LIN_description_file;
LIN_protocol_version = "1.3";
LIN_language_version = "1.3";
LIN_speed = 9.6 kbps;

Nodes {
  Master: BSGEvo, 5 ms, 0.1 ms ;
  Slaves: DNR ;
}

Diagnostic_addresses {
  DNR : 255;
}

Signals {
  DNR_Position_RM: 1, 0, DNR, BSGEvo ;
  DNR_Position_R1: 1, 0, DNR, BSGEvo ;
  DNR_Position_N: 1, 0, DNR, BSGEvo ;
  DNR_Position_D1: 1, 0, DNR, BSGEvo ;
  DNR_Position_D4: 1, 0, DNR, BSGEvo ;
  DNR_Position_D7: 1, 0, DNR, BSGEvo ;
  DNR_Position_DM: 1, 0, DNR, BSGEvo ;
  DNR_Position_MsgCounter: 4, 0, DNR, BSGEvo ;
  DNR_Position_SwitchStatus: 4, 0, DNR, BSGEvo ;
}

Frames {
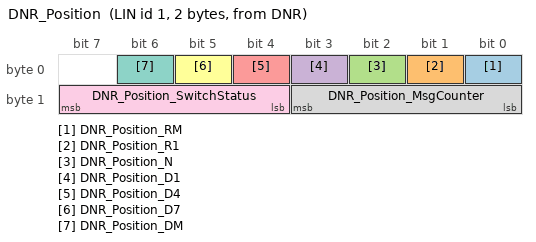
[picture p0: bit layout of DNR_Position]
  DNR_Position: 1, DNR, 2 {
    DNR_Position_RM, 0 ;
    DNR_Position_R1, 1 ;
    DNR_Position_N, 2 ;
    DNR_Position_D1, 3 ;
    DNR_Position_D4, 4 ;
    DNR_Position_D7, 5 ;
    DNR_Position_DM, 6 ;
    DNR_Position_MsgCounter, 8 ;
    DNR_Position_SwitchStatus, 12 ;
  }
}

Schedule_tables {
 Table1 {
    DNR_Position delay 100 ms ;
  }
}

Signal_encoding_types {
  DNR_Position_MsgCounter_Encoding {
    physical_value, 0, 15, 1, 0 ;
  }
  DNR_Position_Selected_Encoding {
    physical_value, 0, 1, 1, 0 ;
    logical_value, 0, "NonSelected" ;
    logical_value, 1, "Selected" ;
  }
  DNR_Position_SwitchStatus_Encoding {
    physical_value, 0, 15, 1, 0 ;
    logical_value, 0, "Switch Position Valid" ;
    logical_value, 1, "2 Contiguous Switching Positions Active" ;
    logical_value, 2, "Switch Defect" ;
    logical_value, 3, "Signal Not Available" ;
  }
}

Signal_representation {
  DNR_Position_MsgCounter_Encoding: DNR_Position_MsgCounter ;
  DNR_Position_Selected_Encoding: DNR_Position_RM, DNR_Position_R1, DNR_Position_N, DNR_Position_D1, DNR_Position_D4, DNR_Position_D7, DNR_Position_DM ;
  DNR_Position_SwitchStatus_Encoding: DNR_Position_SwitchStatus ;
}
